VERSION ""

NS_ :

BS_:

BU_:
	NEO
	MCU
	GTW
	EPAS
	DI
	ESP
	SBW
	STW
	APP
	DAS
	XXX

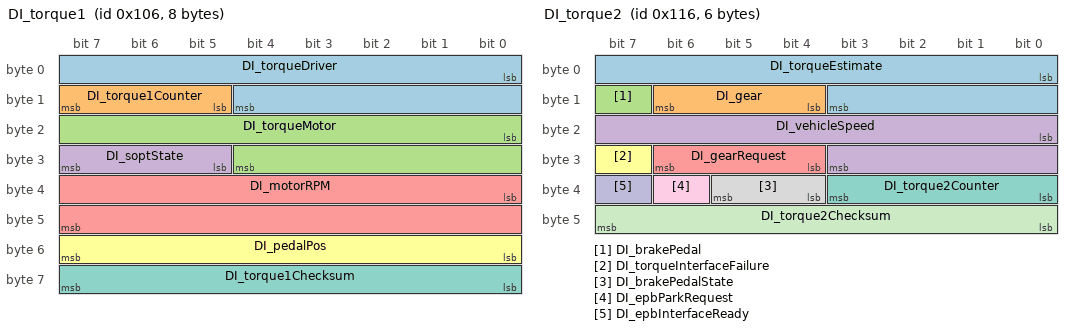
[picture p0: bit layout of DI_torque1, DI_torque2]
BO_ 262 DI_torque1: 8 DI
 SG_ DI_torqueDriver : 0|13@1- (0.25,0) [-750|750] "Nm"  NEO
 SG_ DI_torque1Counter : 13|3@1+ (1,0) [0|0] ""  NEO
 SG_ DI_torqueMotor : 16|13@1- (0.25,0) [-750|750] "Nm"  NEO
 SG_ DI_soptState : 29|3@1+ (1,0) [0|0] ""  NEO
 SG_ DI_motorRPM : 32|16@1- (1,0) [-17000|17000] "RPM"  NEO
 SG_ DI_pedalPos : 48|8@1+ (0.4,0) [0|100] "%"  NEO
 SG_ DI_torque1Checksum : 56|8@1+ (1,0) [0|0] ""  NEO

BO_ 278 DI_torque2: 6 DI
 SG_ DI_torqueEstimate : 0|12@1- (0.5,0) [-750|750] "Nm" NEO
 SG_ DI_gear : 12|3@1+ (1,0) [0|0] "" NEO
 SG_ DI_brakePedal : 15|1@1+ (1,0) [0|0] "" NEO
 SG_ DI_vehicleSpeed : 16|12@1+ (0.05,-25) [-25|179.75] "MPH" NEO
 SG_ DI_gearRequest : 28|3@1+ (1,0) [0|0] "" NEO
 SG_ DI_torqueInterfaceFailure : 31|1@1+ (1,0) [0|0] "" NEO
 SG_ DI_torque2Counter : 32|4@1+ (1,0) [0|0] "" NEO
 SG_ DI_brakePedalState : 36|2@1+ (1,0) [0|0] "" NEO
 SG_ DI_epbParkRequest : 38|1@1+ (1,0) [0|0] "" NEO
 SG_ DI_epbInterfaceReady : 39|1@1+ (1,0) [0|0] "" NEO
 SG_ DI_torque2Checksum : 40|8@1+ (1,0) [0|0] "" NEO

BO_ 504 BrakeMessage: 8 XXX
 SG_ driverBrakeStatus : 2|2@1+ (1,0) [0|3] "" XXX

BO_ 568 STW_ACTN_RQ: 8 STW
 SG_ SpdCtrlLvr_Stat : 0|6@1+ (1,0) [0|0] "" NEO
 SG_ VSL_Enbl_Rq : 6|1@1+ (1,0) [0|0] "" NEO
 SG_ SpdCtrlLvrStat_Inv : 7|1@1+ (1,0) [0|0] "" NEO
 SG_ DTR_Dist_Rq : 8|8@1+ (1,0) [0|200] "" NEO
 SG_ TurnIndLvr_Stat : 16|2@1+ (1,0) [0|0] "" NEO
 SG_ HiBmLvr_Stat : 18|2@1+ (1,0) [0|0] "" NEO
 SG_ WprWashSw_Psd : 20|2@1+ (1,0) [0|0] "" NEO
 SG_ WprWash_R_Sw_Posn_V2 : 22|2@1+ (1,0) [0|0] "" NEO
 SG_ StW_Lvr_Stat : 24|3@1+ (1,0) [0|0] "" NEO
 SG_ StW_Cond_Flt : 27|1@1+ (1,0) [0|0] "" NEO
 SG_ StW_Cond_Psd : 28|2@1+ (1,0) [0|0] "" NEO
 SG_ HrnSw_Psd : 30|2@1+ (1,0) [0|0] "" NEO
 SG_ StW_Sw00_Psd : 32|1@1+ (1,0) [0|0] "" NEO
 SG_ StW_Sw01_Psd : 33|1@1+ (1,0) [0|0] "" NEO
 SG_ StW_Sw02_Psd : 34|1@1+ (1,0) [0|0] "" NEO
 SG_ StW_Sw03_Psd : 35|1@1+ (1,0) [0|0] "" NEO
 SG_ StW_Sw04_Psd : 36|1@1+ (1,0) [0|0] "" NEO
 SG_ StW_Sw05_Psd : 37|1@1+ (1,0) [0|0] "" NEO
 SG_ StW_Sw06_Psd : 38|1@1+ (1,0) [0|0] "" NEO
 SG_ StW_Sw07_Psd : 39|1@1+ (1,0) [0|0] "" NEO
 SG_ StW_Sw08_Psd : 40|1@1+ (1,0) [0|0] "" NEO
 SG_ StW_Sw09_Psd : 41|1@1+ (1,0) [0|0] "" NEO
 SG_ StW_Sw10_Psd : 42|1@1+ (1,0) [0|0] "" NEO
 SG_ StW_Sw11_Psd : 43|1@1+ (1,0) [0|0] "" NEO
 SG_ StW_Sw12_Psd : 44|1@1+ (1,0) [0|0] "" NEO
 SG_ StW_Sw13_Psd : 45|1@1+ (1,0) [0|0] "" NEO
 SG_ StW_Sw14_Psd : 46|1@1+ (1,0) [0|0] "" NEO
 SG_ StW_Sw15_Psd : 47|1@1+ (1,0) [0|0] "" NEO
 SG_ WprSw6Posn : 48|3@1+ (1,0) [0|0] "" NEO
 SG_ MC_STW_ACTN_RQ : 52|4@1+ (1,0) [0|15] "" NEO
 SG_ CRC_STW_ACTN_RQ : 56|8@1+ (1,0) [0|0] "" NEO

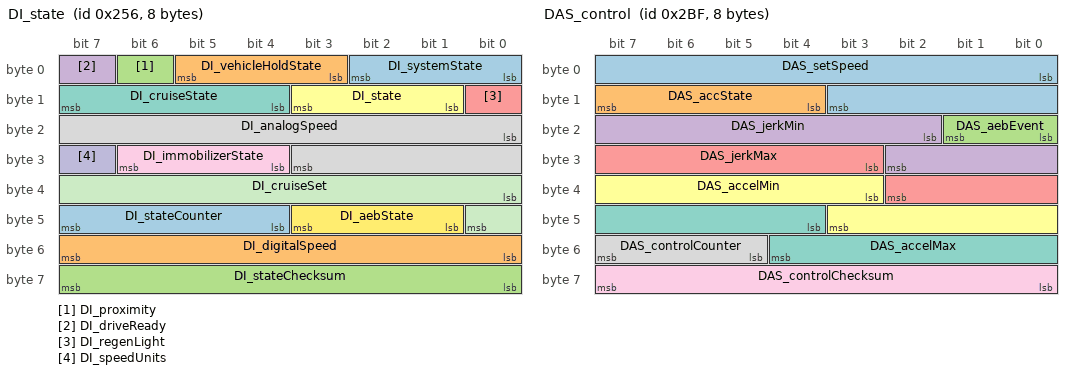
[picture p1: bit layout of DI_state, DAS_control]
BO_ 598 DI_state: 8 DI
 SG_ DI_systemState : 0|3@1+ (1,0) [0|0] ""  NEO
 SG_ DI_vehicleHoldState : 3|3@1+ (1,0) [0|0] ""  NEO
 SG_ DI_proximity : 6|1@1+ (1,0) [0|0] ""  NEO
 SG_ DI_driveReady : 7|1@1+ (1,0) [0|0] ""  NEO
 SG_ DI_regenLight : 8|1@1+ (1,0) [0|0] ""  NEO
 SG_ DI_state : 9|3@1+ (1,0) [0|0] ""  NEO
 SG_ DI_cruiseState : 12|4@1+ (1,0) [0|0] ""  NEO
 SG_ DI_analogSpeed : 16|12@1+ (0.1,0) [0|150] "speed"  NEO
 SG_ DI_immobilizerState : 28|3@1+ (1,0) [0|0] ""  NEO
 SG_ DI_speedUnits : 31|1@1+ (1,0) [0|1] ""  NEO
 SG_ DI_cruiseSet : 32|9@1+ (0.5,0) [0|255.5] "speed"  NEO
 SG_ DI_aebState : 41|3@1+ (1,0) [0|0] ""  NEO
 SG_ DI_stateCounter : 44|4@1+ (1,0) [0|0] ""  NEO
 SG_ DI_digitalSpeed : 48|8@1+ (1,0) [0|250] ""  NEO
 SG_ DI_stateChecksum : 56|8@1+ (1,0) [0|0] ""  NEO

BO_ 703 DAS_control: 8 GTW
 SG_ DAS_setSpeed : 0|12@1+ (0.1,0) [0|409.4] "kph" DI,PM,APS
 SG_ DAS_accState : 12|4@1+ (1,0) [0|0] "" DI,PM,APS
 SG_ DAS_aebEvent : 16|2@1+ (1,0) [0|3] "" DI,PM,APS
 SG_ DAS_jerkMin : 18|9@1+ (0.03,-15.232) [-15.232|0.098] "m/s^3" DI,PM,APS
 SG_ DAS_jerkMax : 27|8@1+ (0.059,0) [0|15.045] "m/s^3" DI,PM,APS
 SG_ DAS_accelMin : 35|9@1+ (0.04,-15) [-15|5.44] "m/s^2" DI,PM,APS
 SG_ DAS_accelMax : 44|9@1+ (0.04,-15) [-15|5.44] "m/s^2" DI,PM,APS
 SG_ DAS_controlCounter : 53|3@1+ (1,0) [0|0] "" DI,PM,APS
 SG_ DAS_controlChecksum : 56|8@1+ (1,0) [0|0] "" DI,PM,APS

BO_ 913 DAS_status: 8 GTW
 SG_ DAS_autopilotState : 0|4@1+ (1,0) [0|0] "" APS
 SG_ DAS_blindSpotRearLeft : 4|2@1+ (1,0) [0|0] "" APS
 SG_ DAS_blindSpotRearRight : 6|2@1+ (1,0) [0|0] "" APS
 SG_ DAS_fusedSpeedLimit : 8|5@1+ (5,0) [0|150] "kph/mph" APS
 SG_ DAS_suppressSpeedWarning : 13|1@1+ (1,0) [0|0] "" APS
 SG_ DAS_summonObstacle : 14|1@1+ (1,0) [0|0] "" APS
 SG_ DAS_summonClearedGate : 15|1@1+ (1,0) [0|0] "" APS
 SG_ DAS_visionOnlySpeedLimit : 16|5@1+ (5,0) [0|150] "kph/mph" APS
 SG_ DAS_heaterState : 21|1@1+ (1,0) [0|0] "" THC
 SG_ DAS_forwardCollisionWarning : 22|2@1+ (1,0) [0|0] "" APS
 SG_ DAS_autoparkReady : 24|1@1+ (1,0) [0|1] "" APS
 SG_ DAS_autoParked : 25|1@1+ (1,0) [0|0] "" APS
 SG_ DAS_autoparkWaitingForBrake : 26|1@1+ (1,0) [0|1] "" APS
 SG_ DAS_summonFwdLeashReached : 27|1@1+ (1,0) [0|1] "" APS
 SG_ DAS_summonRvsLeashReached : 28|1@1+ (1,0) [0|1] "" APS
 SG_ DAS_lssState : 29|3@1+ (1,0) [0|0] "" APS
 SG_ DAS_sideCollisionAvoid : 32|2@1+ (1,0) [0|0] "" APS
 SG_ DAS_sideCollisionWarning : 34|2@1+ (1,0) [0|0] "" APS
 SG_ DAS_sideCollisionInhibit : 36|1@1+ (1,0) [0|0] "" APS
 SG_ DAS_laneDepartureWarning : 37|3@1+ (1,0) [0|0] "" APS
 SG_ DAS_fleetSpeedState : 40|2@1+ (1,0) [0|0] "" APS
 SG_ DAS_autopilotHandsOnState : 42|4@1+ (1,0) [0|0] "" APS
 SG_ DAS_autoLaneChangeState : 46|5@1+ (1,0) [0|0] "" APS
 SG_ DAS_summonAvailable : 51|1@1+ (1,0) [0|1] "" APS
 SG_ DAS_statusCounter : 52|4@1+ (1,0) [0|0] "" APS
 SG_ DAS_statusChecksum : 56|8@1+ (1,0) [0|0] "" APS

VAL_ 262 DI_torqueDriver -4096 "SNA" ;
VAL_ 262 DI_torqueMotor -4096 "SNA" ;
VAL_ 262 DI_soptState 7 "SOPT_TEST_SNA" 4 "SOPT_TEST_NOT_RUN" 3 "SOPT_TEST_PASSED" 2 "SOPT_TEST_FAILED" 1 "SOPT_TEST_IN_PROGRESS" 0 "SOPT_PRE_TEST" ;
VAL_ 262 DI_motorRPM -32768 "SNA" ;
VAL_ 262 DI_pedalPos 255 "SNA" ;
VAL_ 278 DI_torqueEstimate -2048 "SNA" ;
VAL_ 278 DI_gear 7 "DI_GEAR_SNA" 4 "DI_GEAR_D" 3 "DI_GEAR_N" 2 "DI_GEAR_R" 1 "DI_GEAR_P" 0 "DI_GEAR_INVALID" ;
VAL_ 278 DI_brakePedal 1 "Applied" 0 "Not_applied" ;
VAL_ 278 DI_vehicleSpeed 4095 "SNA" ;
VAL_ 278 DI_gearRequest 7 "DI_GEAR_SNA" 4 "DI_GEAR_D" 3 "DI_GEAR_N" 2 "DI_GEAR_R" 1 "DI_GEAR_P" 0 "DI_GEAR_INVALID" ;
VAL_ 278 DI_torqueInterfaceFailure 1 "TORQUE_INTERFACE_FAILED" 0 "TORQUE_INTERFACE_NORMAL" ;
VAL_ 278 DI_brakePedalState 3 "SNA" 2 "INVALID" 1 "ON" 0 "OFF" ;
VAL_ 278 DI_epbParkRequest 1 "Park_requested" 0 "No_request" ;
VAL_ 278 DI_epbInterfaceReady 1 "EPB_INTERFACE_READY" 0 "EPB_INTERFACE_NOT_READY" ;
VAL_ 504 driverBrakeStatus 2 "APPLIED" 1 "NOT_APPLIED" ;
VAL_ 568 SpdCtrlLvr_Stat 32 "DN_1ST" 16 "UP_1ST" 8 "DN_2ND" 4 "UP_2ND" 2 "RWD" 1 "FWD" 0 "IDLE" ;
VAL_ 568 DTR_Dist_Rq 255 "SNA" 200 "ACC_DIST_7" 166 "ACC_DIST_6" 133 "ACC_DIST_5" 100 "ACC_DIST_4" 66 "ACC_DIST_3" 33 "ACC_DIST_2" 0 "ACC_DIST_1" ;
VAL_ 568 TurnIndLvr_Stat 3 "SNA" 2 "RIGHT" 1 "LEFT" 0 "IDLE" ;
VAL_ 568 HiBmLvr_Stat 3 "SNA" 2 "HIBM_FLSH_ON_PSD" 1 "HIBM_ON_PSD" 0 "IDLE" ;
VAL_ 568 WprWashSw_Psd 3 "SNA" 2 "WASH" 1 "TIPWIPE" 0 "NPSD" ;
VAL_ 568 WprWash_R_Sw_Posn_V2 3 "SNA" 2 "WASH" 1 "INTERVAL" 0 "OFF" ;
VAL_ 568 StW_Lvr_Stat 4 "STW_BACK" 3 "STW_FWD" 2 "STW_DOWN" 1 "STW_UP" 0 "NPSD" ;
VAL_ 568 StW_Cond_Psd 3 "SNA" 2 "DOWN" 1 "UP" 0 "NPSD" ;
VAL_ 568 HrnSw_Psd 3 "SNA" 2 "NDEF2" 1 "PSD" 0 "NPSD" ;
VAL_ 568 StW_Sw00_Psd 1 "PRESSED" 0 "NOT_PRESSED_SNA" ;
VAL_ 568 StW_Sw01_Psd 1 "PRESSED" 0 "NOT_PRESSED_SNA" ;
VAL_ 568 StW_Sw03_Psd 1 "PRESSED" 0 "NOT_PRESSED_SNA" ;
VAL_ 568 StW_Sw04_Psd 1 "PRESSED" 0 "NOT_PRESSED_SNA" ;
VAL_ 568 WprSw6Posn 7 "SNA" 6 "STAGE2" 5 "STAGE1" 4 "INTERVAL4" 3 "INTERVAL3" 2 "INTERVAL2" 1 "INTERVAL1" 0 "OFF" ;
VAL_ 598 DI_aebState 2 "ENABLED" 4 "FAULT" 7 "SNA" 1 "STANDBY" 3 "STANDSTILL" 0 "UNAVAILABLE" ;
VAL_ 598 DI_analogSpeed 4095 "SNA" ;
VAL_ 598 DI_cruiseState 2 "ENABLED" 5 "FAULT" 0 "OFF" 4 "OVERRIDE" 7 "PRE_CANCEL" 6 "PRE_FAULT" 1 "STANDBY" 3 "STANDSTILL" ;
VAL_ 598 DI_digitalSpeed 255 "SNA" ;
VAL_ 598 DI_immobilizerState 2 "AUTHENTICATING" 3 "DISARMED" 6 "FAULT" 4 "IDLE" 0 "INIT_SNA" 1 "REQUEST" 5 "RESET" ;
VAL_ 598 DI_speedUnits 1 "KPH" 0 "MPH" ;
VAL_ 598 DI_state 3 "ABORT" 4 "ENABLE" 2 "FAULT" 1 "STANDBY" 0 "UNAVAILABLE" ;
VAL_ 598 DI_systemState 3 "ABORT" 4 "ENABLE" 2 "FAULT" 1 "STANDBY" 0 "UNAVAILABLE" ;
VAL_ 598 DI_vehicleHoldState 2 "BLEND_IN" 4 "BLEND_OUT" 6 "FAULT" 7 "INIT" 5 "PARK" 1 "STANDBY" 3 "STANDSTILL" 0 "UNAVAILABLE" ;
VAL_ 703 DAS_setSpeed 4095 "SNA" ;
VAL_ 703 DAS_accState 15 "FAULT_SNA" 13 "ACC_CANCEL_GENERIC_SILENT" 11 "APC_SELFPARK_START" 10 "APC_UNPARK_COMPLETE" 9 "APC_PAUSE" 8 "APC_ABORT" 7 "APC_COMPLETE" 6 "APC_FORWARD" 5 "APC_BACKWARD" 4 "ACC_ON" 3 "ACC_HOLD" 0 "ACC_CANCEL_GENERIC" ;
VAL_ 703 DAS_aebEvent 3 "AEB_SNA" 2 "AEB_FAULT" 1 "AEB_ACTIVE" 0 "AEB_NOT_ACTIVE" ;
VAL_ 703 DAS_jerkMin 511 "SNA" ;
VAL_ 703 DAS_jerkMax 255 "SNA" ;
VAL_ 703 DAS_accelMin 511 "SNA" ;
VAL_ 703 DAS_accelMax 511 "SNA" ;
VAL_ 913 DAS_autopilotState 15 "SNA" 14 "FAULT" 9 "ABORTED" 8 "ABORTING" 5 "ACTIVE_NAV" 4 "ACTIVE_RESTRICTED" 3 "ACTIVE_NOMINAL" 2 "AVAILABLE" 1 "UNAVAILABLE" 0 "DISABLED" ;
VAL_ 913 DAS_blindSpotRearLeft 3 "SNA" 2 "WARNING_LEVEL_2" 1 "WARNING_LEVEL_1" 0 "NO_WARNING" ;
VAL_ 913 DAS_blindSpotRearRight 3 "SNA" 2 "WARNING_LEVEL_2" 1 "WARNING_LEVEL_1" 0 "NO_WARNING" ;
VAL_ 913 DAS_fusedSpeedLimit 31 "NONE" 0 "UNKNOWN_SNA" ;
VAL_ 913 DAS_suppressSpeedWarning 1 "Suppress_Speed_Warning" 0 "Do_Not_Suppress" ;
VAL_ 913 DAS_visionOnlySpeedLimit 31 "NONE" 0 "UNKNOWN_SNA" ;
VAL_ 913 DAS_heaterState 1 "HEATER_ON" 0 "HEATER_OFF_SNA" ;
VAL_ 913 DAS_forwardCollisionWarning 3 "SNA" 1 "FORWARD_COLLISION_WARNING" 0 "NONE" ;
VAL_ 913 DAS_autoparkReady 1 "AUTOPARK_READY" 0 "AUTOPARK_UNAVAILABLE" ;
VAL_ 913 DAS_lssState 7 "LSS_STATE_OFF" 6 "LSS_STATE_ABORT" 5 "LSS_STATE_BLINDSPOT" 4 "LSS_STATE_MONITOR" 3 "LSS_STATE_ELK" 2 "LSS_STATE_LKA" 1 "LSS_STATE_LDW" 0 "LSS_STATE_FAULT" ;
VAL_ 913 DAS_sideCollisionAvoid 3 "SNA" 2 "AVOID_RIGHT" 1 "AVOID_LEFT" 0 "NONE" ;
VAL_ 913 DAS_sideCollisionWarning 3 "WARN_LEFT_RIGHT" 2 "WARN_RIGHT" 1 "WARN_LEFT" 0 "NONE" ;
VAL_ 913 DAS_sideCollisionInhibit 1 "INHIBIT" 0 "NO_INHIBIT" ;
VAL_ 913 DAS_laneDepartureWarning 5 "SNA" 4 "RIGHT_WARNING_SEVERE" 3 "LEFT_WARNING_SEVERE" 2 "RIGHT_WARNING" 1 "LEFT_WARNING" 0 "NONE" ;
VAL_ 913 DAS_fleetSpeedState 3 "FLEETSPEED_HOLD" 2 "FLEETSPEED_ACTIVE" 1 "FLEETSPEED_AVAILABLE" 0 "FLEETSPEED_UNAVAILABLE" ;
VAL_ 913 DAS_autopilotHandsOnState 15 "LC_HANDS_ON_SNA" 10 "LC_HANDS_ON_REQD_ESCALATED_CHIME_2" 9 "LC_HANDS_ON_REQD_ESCALATED_CHIME_1" 8 "LC_HANDS_ON_SUSPENDED" 7 "LC_HANDS_ON_REQD_STRUCK_OUT" 5 "LC_HANDS_ON_REQD_CHIME_2" 4 "LC_HANDS_ON_REQD_CHIME_1" 3 "LC_HANDS_ON_REQD_VISUAL" 2 "LC_HANDS_ON_REQD_NOT_DETECTED" 1 "LC_HANDS_ON_REQD_DETECTED" 0 "LC_HANDS_ON_NOT_REQD" ;
VAL_ 913 DAS_autoLaneChangeState 31 "ALC_SNA" 30 "ALC_ABORT_MISSION_PLAN_INVALID" 29 "ALC_ABORT_TIMEOUT" 28 "ALC_WAITING_HANDS_ON" 27 "ALC_BLOCKED_LANE_TYPE_R" 26 "ALC_BLOCKED_LANE_TYPE_L" 25 "ALC_BLOCKED_VEH_TTC_AND_USS_R" 24 "ALC_BLOCKED_VEH_TTC_R" 23 "ALC_BLOCKED_VEH_TTC_AND_USS_L" 22 "ALC_BLOCKED_VEH_TTC_L" 21 "ALC_UNAVAILABLE_SOLID_LANE_LINE" 20 "ALC_ABORT_OTHER_REASON" 19 "ALC_ABORT_BLINKER_TURNED_OFF" 18 "ALC_ABORT_LC_HEALTH_BAD" 17 "ALC_ABORT_POOR_VIEW_RANGE" 16 "ALC_ABORT_SIDE_OBSTACLE_PRESENT_R" 15 "ALC_ABORT_SIDE_OBSTACLE_PRESENT_L" 14 "ALC_WAITING_FOR_FWD_OBST_TO_PASS_R" 13 "ALC_WAITING_FOR_FWD_OBST_TO_PASS_L" 12 "ALC_WAITING_FOR_SIDE_OBST_TO_PASS_R" 11 "ALC_WAITING_FOR_SIDE_OBST_TO_PASS_L" 10 "ALC_IN_PROGRESS_R" 9 "ALC_IN_PROGRESS_L" 8 "ALC_AVAILABLE_BOTH" 7 "ALC_AVAILABLE_ONLY_R" 6 "ALC_AVAILABLE_ONLY_L" 5 "ALC_UNAVAILABLE_VEHICLE_SPEED" 4 "ALC_UNAVAILABLE_EXITING_HIGHWAY" 3 "ALC_UNAVAILABLE_TP_FOLLOW" 2 "ALC_UNAVAILABLE_SONICS_INVALID" 1 "ALC_UNAVAILABLE_NO_LANES" 0 "ALC_UNAVAILABLE_DISABLED" ;
